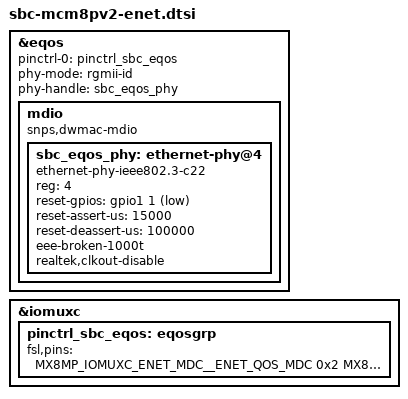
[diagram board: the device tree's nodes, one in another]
// SPDX-License-Identifier: (GPL-2.0+ OR MIT)
/* Copyright 2026 CompuLab Ltd. */

&eqos {
	pinctrl-names = "default";
	pinctrl-0 = <&pinctrl_sbc_eqos>;
	phy-mode = "rgmii-id";
	phy-handle = <&sbc_eqos_phy>;
	status = "okay";

	mdio {
		compatible = "snps,dwmac-mdio";
		#address-cells = <1>;
		#size-cells = <0>;

		sbc_eqos_phy: ethernet-phy@4 {
			compatible = "ethernet-phy-ieee802.3-c22";
			reg = <4>;
			reset-gpios = <&gpio1 1 GPIO_ACTIVE_LOW>;
			reset-assert-us = <15000>;
			reset-deassert-us = <100000>;
			eee-broken-1000t;
			realtek,clkout-disable;
		};
	};
};

&iomuxc {
	pinctrl_sbc_eqos: eqosgrp {
		fsl,pins = <
			MX8MP_IOMUXC_ENET_MDC__ENET_QOS_MDC				0x2
			MX8MP_IOMUXC_ENET_MDIO__ENET_QOS_MDIO				0x2
			MX8MP_IOMUXC_ENET_RD0__ENET_QOS_RGMII_RD0			0x90
			MX8MP_IOMUXC_ENET_RD1__ENET_QOS_RGMII_RD1			0x90
			MX8MP_IOMUXC_ENET_RD2__ENET_QOS_RGMII_RD2			0x90
			MX8MP_IOMUXC_ENET_RD3__ENET_QOS_RGMII_RD3			0x90
			MX8MP_IOMUXC_ENET_RXC__CCM_ENET_QOS_CLOCK_GENERATE_RX_CLK	0x90
			MX8MP_IOMUXC_ENET_RX_CTL__ENET_QOS_RGMII_RX_CTL			0x90
			MX8MP_IOMUXC_ENET_TD0__ENET_QOS_RGMII_TD0			0x16
			MX8MP_IOMUXC_ENET_TD1__ENET_QOS_RGMII_TD1			0x16
			MX8MP_IOMUXC_ENET_TD2__ENET_QOS_RGMII_TD2			0x16
			MX8MP_IOMUXC_ENET_TD3__ENET_QOS_RGMII_TD3			0x16
			MX8MP_IOMUXC_ENET_TX_CTL__ENET_QOS_RGMII_TX_CTL			0x16
			MX8MP_IOMUXC_ENET_TXC__CCM_ENET_QOS_CLOCK_GENERATE_TX_CLK	0x16
			MX8MP_IOMUXC_GPIO1_IO01__GPIO1_IO01				0x10
		>;
	};
};
